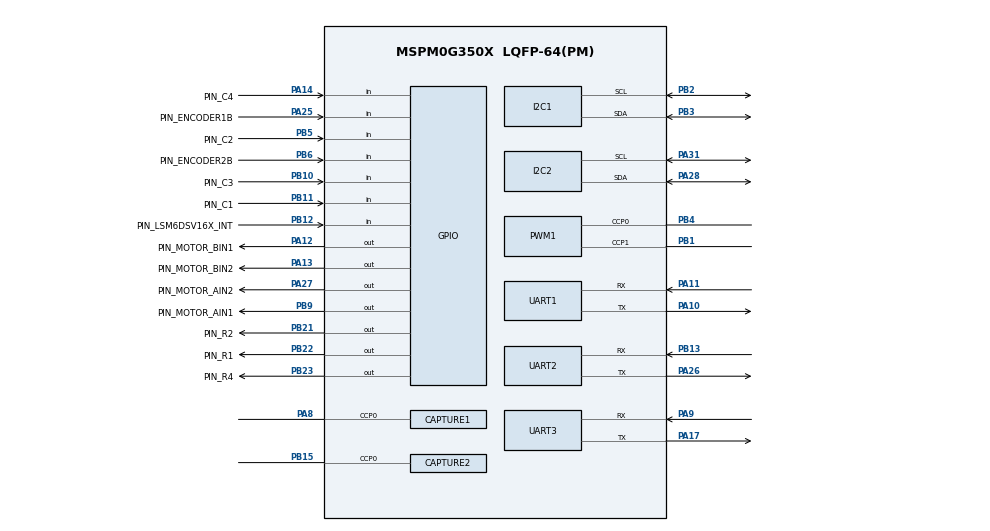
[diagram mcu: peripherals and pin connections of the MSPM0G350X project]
/**
 * @cliArgs --device "MSPM0G350X" --part "Default" --package "LQFP-64(PM)" --product "mspm0_sdk@2.05.00.05"
 * @versions {"tool":"1.24.0+4110"}
 */

/**
 * Import the modules used in this configuration.
 */
const CAPTURE  = scripting.addModule("/ti/driverlib/CAPTURE", {}, false);
const CAPTURE1 = CAPTURE.addInstance();
const CAPTURE2 = CAPTURE.addInstance();
const DMA      = scripting.addModule("/ti/driverlib/DMA");
const GPIO     = scripting.addModule("/ti/driverlib/GPIO", {}, false);
const GPIO1    = GPIO.addInstance();
const GPIO2    = GPIO.addInstance();
const GPIO3    = GPIO.addInstance();
const GPIO4    = GPIO.addInstance();
const I2C      = scripting.addModule("/ti/driverlib/I2C", {}, false);
const I2C1     = I2C.addInstance();
const I2C2     = I2C.addInstance();
const PWM      = scripting.addModule("/ti/driverlib/PWM", {}, false);
const PWM1     = PWM.addInstance();
const SYSCTL   = scripting.addModule("/ti/driverlib/SYSCTL");
const TIMER    = scripting.addModule("/ti/driverlib/TIMER", {}, false);
const TIMER1   = TIMER.addInstance();
const TIMER2   = TIMER.addInstance();
const UART     = scripting.addModule("/ti/driverlib/UART", {}, false);
const UART1    = UART.addInstance();
const UART2    = UART.addInstance();
const UART3    = UART.addInstance();

/**
 * Write custom configuration values to the imported modules.
 */
const divider7       = system.clockTree["PLL_PDIV"];
divider7.divideValue = 2;

const divider9       = system.clockTree["UDIV"];
divider9.divideValue = 2;

const multiplier2         = system.clockTree["PLL_QDIV"];
multiplier2.multiplyValue = 5;

const mux8       = system.clockTree["HSCLKMUX"];
mux8.inputSelect = "HSCLKMUX_SYSPLL2X";

CAPTURE1.$name                              = "ENCODER1A";
CAPTURE1.timerPeriod                        = "1 ms";
CAPTURE1.timerClkPrescale                   = 2;
CAPTURE1.interrupts                         = ["CC0_DN"];
CAPTURE1.timerStartTimer                    = true;
CAPTURE1.peripheral.ccp0Pin.$assign         = "PA8";
CAPTURE1.ccp0PinConfig.hideOutputInversion  = scripting.forceWrite(false);
CAPTURE1.ccp0PinConfig.onlyInternalResistor = scripting.forceWrite(false);
CAPTURE1.ccp0PinConfig.passedPeripheralType = scripting.forceWrite("Digital");
CAPTURE1.ccp0PinConfig.$name                = "ti_driverlib_gpio_GPIOPinGeneric6";

const Board = scripting.addModule("/ti/driverlib/Board", {}, false);

CAPTURE2.$name                              = "ENCODER2A";
CAPTURE2.timerPeriod                        = "1 ms";
CAPTURE2.timerStartTimer                    = true;
CAPTURE2.interrupts                         = ["CC0_DN"];
CAPTURE2.timerClkPrescale                   = 2;
CAPTURE2.peripheral.ccp0Pin.$assign         = "PB15";
CAPTURE2.ccp0PinConfig.hideOutputInversion  = scripting.forceWrite(false);
CAPTURE2.ccp0PinConfig.onlyInternalResistor = scripting.forceWrite(false);
CAPTURE2.ccp0PinConfig.passedPeripheralType = scripting.forceWrite("Digital");
CAPTURE2.ccp0PinConfig.$name                = "ti_driverlib_gpio_GPIOPinGeneric7";

GPIO1.$name                              = "GPIO_KEY";
GPIO1.associatedPins.create(8);
GPIO1.associatedPins[0].$name            = "PIN_C3";
GPIO1.associatedPins[0].direction        = "INPUT";
GPIO1.associatedPins[0].internalResistor = "PULL_UP";
GPIO1.associatedPins[0].assignedPort     = "PORTB";
GPIO1.associatedPins[0].assignedPin      = "10";
GPIO1.associatedPins[0].pin.$assign      = "PB10";
GPIO1.associatedPins[1].$name            = "PIN_C4";
GPIO1.associatedPins[1].direction        = "INPUT";
GPIO1.associatedPins[1].internalResistor = "PULL_UP";
GPIO1.associatedPins[1].assignedPort     = "PORTA";
GPIO1.associatedPins[1].assignedPin      = "14";
GPIO1.associatedPins[1].pin.$assign      = "PA14";
GPIO1.associatedPins[2].$name            = "PIN_R1";
GPIO1.associatedPins[2].initialValue     = "SET";
GPIO1.associatedPins[2].assignedPort     = "PORTB";
GPIO1.associatedPins[2].assignedPin      = "22";
GPIO1.associatedPins[2].pin.$assign      = "PB22";
GPIO1.associatedPins[3].$name            = "PIN_R2";
GPIO1.associatedPins[3].initialValue     = "SET";
GPIO1.associatedPins[3].assignedPort     = "PORTB";
GPIO1.associatedPins[3].assignedPin      = "21";
GPIO1.associatedPins[3].pin.$assign      = "PB21";
GPIO1.associatedPins[4].$name            = "PIN_R3";
GPIO1.associatedPins[4].initialValue     = "SET";
GPIO1.associatedPins[4].assignedPort     = "PORTB";
GPIO1.associatedPins[4].assignedPin      = "26";
GPIO1.associatedPins[5].$name            = "PIN_R4";
GPIO1.associatedPins[5].initialValue     = "SET";
GPIO1.associatedPins[5].assignedPort     = "PORTB";
GPIO1.associatedPins[5].assignedPin      = "23";
GPIO1.associatedPins[5].pin.$assign      = "PB23";
GPIO1.associatedPins[6].$name            = "PIN_C1";
GPIO1.associatedPins[6].direction        = "INPUT";
GPIO1.associatedPins[6].internalResistor = "PULL_UP";
GPIO1.associatedPins[6].assignedPort     = "PORTB";
GPIO1.associatedPins[6].assignedPin      = "11";
GPIO1.associatedPins[6].pin.$assign      = "PB11";
GPIO1.associatedPins[7].$name            = "PIN_C2";
GPIO1.associatedPins[7].direction        = "INPUT";
GPIO1.associatedPins[7].internalResistor = "PULL_UP";
GPIO1.associatedPins[7].assignedPort     = "PORTB";
GPIO1.associatedPins[7].assignedPin      = "5";
GPIO1.associatedPins[7].pin.$assign      = "PB5";

GPIO2.$name                         = "GPIO_MOTOR";
GPIO2.associatedPins.create(4);
GPIO2.associatedPins[0].$name       = "PIN_MOTOR_AIN1";
GPIO2.associatedPins[0].pin.$assign = "PB9";
GPIO2.associatedPins[1].$name       = "PIN_MOTOR_AIN2";
GPIO2.associatedPins[1].pin.$assign = "PA27";
GPIO2.associatedPins[2].$name       = "PIN_MOTOR_BIN1";
GPIO2.associatedPins[2].pin.$assign = "PA12";
GPIO2.associatedPins[3].$name       = "PIN_MOTOR_BIN2";
GPIO2.associatedPins[3].pin.$assign = "PA13";

GPIO3.$name                               = "GPIO_ENCODER";
GPIO3.associatedPins.create(2);
GPIO3.associatedPins[0].$name             = "PIN_ENCODER1B";
GPIO3.associatedPins[0].direction         = "INPUT";
GPIO3.associatedPins[0].pin.$assign       = "PA25";
GPIO3.associatedPins[1].direction         = "INPUT";
GPIO3.associatedPins[1].polarity          = "RISE";
GPIO3.associatedPins[1].interruptPriority = "1";
GPIO3.associatedPins[1].$name             = "PIN_ENCODER2B";
GPIO3.associatedPins[1].pin.$assign       = "PB6";

GPIO4.$name                               = "GPIO_LSM6DSV16X";
GPIO4.associatedPins[0].$name             = "PIN_LSM6DSV16X_INT";
GPIO4.associatedPins[0].direction         = "INPUT";
GPIO4.associatedPins[0].interruptEn       = true;
GPIO4.associatedPins[0].polarity          = "RISE";
GPIO4.associatedPins[0].interruptPriority = "3";
GPIO4.associatedPins[0].pin.$assign       = "PB12";

I2C1.$name                             = "I2C_OLED";
I2C1.basicEnableController             = true;
I2C1.basicControllerStandardBusSpeed   = "Fast";
I2C1.peripheral.sdaPin.$assign         = "PB3";
I2C1.peripheral.sclPin.$assign         = "PB2";
I2C1.sdaPinConfig.hideOutputInversion  = scripting.forceWrite(false);
I2C1.sdaPinConfig.onlyInternalResistor = scripting.forceWrite(false);
I2C1.sdaPinConfig.passedPeripheralType = scripting.forceWrite("Digital");
I2C1.sdaPinConfig.$name                = "ti_driverlib_gpio_GPIOPinGeneric0";
I2C1.sclPinConfig.hideOutputInversion  = scripting.forceWrite(false);
I2C1.sclPinConfig.onlyInternalResistor = scripting.forceWrite(false);
I2C1.sclPinConfig.passedPeripheralType = scripting.forceWrite("Digital");
I2C1.sclPinConfig.$name                = "ti_driverlib_gpio_GPIOPinGeneric1";

I2C2.$name                             = "I2C_LSM6DSV16X";
I2C2.basicEnableController             = true;
I2C2.peripheral.$assign                = "I2C0";
I2C2.peripheral.sdaPin.$assign         = "PA28";
I2C2.peripheral.sclPin.$assign         = "PA31";
I2C2.sdaPinConfig.hideOutputInversion  = scripting.forceWrite(false);
I2C2.sdaPinConfig.onlyInternalResistor = scripting.forceWrite(false);
I2C2.sdaPinConfig.passedPeripheralType = scripting.forceWrite("Digital");
I2C2.sdaPinConfig.$name                = "ti_driverlib_gpio_GPIOPinGeneric8";
I2C2.sclPinConfig.hideOutputInversion  = scripting.forceWrite(false);
I2C2.sclPinConfig.onlyInternalResistor = scripting.forceWrite(false);
I2C2.sclPinConfig.passedPeripheralType = scripting.forceWrite("Digital");
I2C2.sclPinConfig.$name                = "ti_driverlib_gpio_GPIOPinGeneric9";

PWM1.clockDivider                       = 2;
PWM1.timerCount                         = 4000;
PWM1.timerStartTimer                    = true;
PWM1.$name                              = "PWM_MOTOR_1";
PWM1.pwmMode                            = "EDGE_ALIGN_UP";
PWM1.peripheral.ccp0Pin.$assign         = "PB4";
PWM1.peripheral.ccp1Pin.$assign         = "PB1";
PWM1.PWM_CHANNEL_0.$name                = "ti_driverlib_pwm_PWMTimerCC0";
PWM1.PWM_CHANNEL_1.$name                = "ti_driverlib_pwm_PWMTimerCC1";
PWM1.ccp0PinConfig.direction            = scripting.forceWrite("OUTPUT");
PWM1.ccp0PinConfig.hideOutputInversion  = scripting.forceWrite(false);
PWM1.ccp0PinConfig.onlyInternalResistor = scripting.forceWrite(false);
PWM1.ccp0PinConfig.passedPeripheralType = scripting.forceWrite("Digital");
PWM1.ccp0PinConfig.$name                = "ti_driverlib_gpio_GPIOPinGeneric2";
PWM1.ccp1PinConfig.direction            = scripting.forceWrite("OUTPUT");
PWM1.ccp1PinConfig.hideOutputInversion  = scripting.forceWrite(false);
PWM1.ccp1PinConfig.onlyInternalResistor = scripting.forceWrite(false);
PWM1.ccp1PinConfig.passedPeripheralType = scripting.forceWrite("Digital");
PWM1.ccp1PinConfig.$name                = "ti_driverlib_gpio_GPIOPinGeneric5";

SYSCTL.forceDefaultClkConfig = true;
SYSCTL.clockTreeEn           = true;
scripting.suppress("For best practices when the CPUCLK is running at 32MHz and above, clear the flash status bit using DL_FlashCTL_executeClearStatus\\(\\) before executing any flash operation\\. Otherwise there may be false positives\\.", SYSCTL);

TIMER1.$name            = "CLOCK_ZYD";
TIMER1.timerClkDiv      = 4;
TIMER1.timerMode        = "PERIODIC";
TIMER1.interrupts       = ["ZERO"];
TIMER1.timerStartTimer  = true;
TIMER1.timerClkPrescale = 50;
TIMER1.timerPeriod      = "10 ms";

TIMER2.$name            = "CLOCK_PTZ";
TIMER2.timerClkDiv      = 8;
TIMER2.timerMode        = "PERIODIC";
TIMER2.timerClkPrescale = 10;
TIMER2.interrupts       = ["ZERO"];
TIMER2.timerStartTimer  = true;
TIMER2.timerPeriod      = "80 ms";

UART1.targetBaudRate                       = 115200;
UART1.$name                                = "UART_K230";
UART1.enabledDMARXTriggers                 = "DL_UART_DMA_INTERRUPT_RX";
UART1.enabledInterrupts                    = ["RX"];
UART1.txFifoThreshold                      = "DL_UART_TX_FIFO_LEVEL_EMPTY";
UART1.enableFIFO                           = true;
UART1.rxFifoThreshold                      = "DL_UART_RX_FIFO_LEVEL_FULL";
UART1.peripheral.$assign                   = "UART0";
UART1.peripheral.rxPin.$assign             = "PA11";
UART1.peripheral.txPin.$assign             = "PA10";
UART1.txPinConfig.direction                = scripting.forceWrite("OUTPUT");
UART1.txPinConfig.hideOutputInversion      = scripting.forceWrite(false);
UART1.txPinConfig.onlyInternalResistor     = scripting.forceWrite(false);
UART1.txPinConfig.passedPeripheralType     = scripting.forceWrite("Digital");
UART1.txPinConfig.$name                    = "ti_driverlib_gpio_GPIOPinGeneric3";
UART1.rxPinConfig.hideOutputInversion      = scripting.forceWrite(false);
UART1.rxPinConfig.onlyInternalResistor     = scripting.forceWrite(false);
UART1.rxPinConfig.passedPeripheralType     = scripting.forceWrite("Digital");
UART1.rxPinConfig.$name                    = "ti_driverlib_gpio_GPIOPinGeneric4";
UART1.DMA_CHANNEL_RX.$name                 = "DMA_CH0";
UART1.DMA_CHANNEL_RX.addressMode           = "f2b";
UART1.DMA_CHANNEL_RX.srcLength             = "BYTE";
UART1.DMA_CHANNEL_RX.dstLength             = "BYTE";
UART1.DMA_CHANNEL_RX.configureTransferSize = true;
UART1.DMA_CHANNEL_RX.enableInterrupt       = true;
UART1.DMA_CHANNEL_RX.transferSize          = 7;
UART1.DMA_CHANNEL_RX.peripheral.$assign    = "DMA_CH0";

UART2.$name                                = "UART_FORWORD";
UART2.targetBaudRate                       = 115200;
UART2.enabledDMARXTriggers                 = "DL_UART_DMA_INTERRUPT_RX";
UART2.enabledDMATXTriggers                 = "DL_UART_DMA_INTERRUPT_TX";
UART2.enabledInterrupts                    = ["DMA_DONE_RX","EOT_DONE"];
UART2.txFifoThreshold                      = "DL_UART_TX_FIFO_LEVEL_EMPTY";
UART2.rxFifoThreshold                      = "DL_UART_RX_FIFO_LEVEL_ONE_ENTRY";
UART2.peripheral.rxPin.$assign             = "PB13";
UART2.peripheral.txPin.$assign             = "PA26";
UART2.txPinConfig.$name                    = "ti_driverlib_gpio_GPIOPinGeneric10";
UART2.txPinConfig.direction                = scripting.forceWrite("OUTPUT");
UART2.txPinConfig.hideOutputInversion      = scripting.forceWrite(false);
UART2.txPinConfig.onlyInternalResistor     = scripting.forceWrite(false);
UART2.txPinConfig.passedPeripheralType     = scripting.forceWrite("Digital");
UART2.rxPinConfig.$name                    = "ti_driverlib_gpio_GPIOPinGeneric11";
UART2.rxPinConfig.hideOutputInversion      = scripting.forceWrite(false);
UART2.rxPinConfig.onlyInternalResistor     = scripting.forceWrite(false);
UART2.rxPinConfig.passedPeripheralType     = scripting.forceWrite("Digital");
UART2.DMA_CHANNEL_RX.$name                 = "DMA_CH1";
UART2.DMA_CHANNEL_RX.addressMode           = "f2b";
UART2.DMA_CHANNEL_RX.srcLength             = "BYTE";
UART2.DMA_CHANNEL_RX.dstLength             = "BYTE";
UART2.DMA_CHANNEL_RX.enableInterrupt       = true;
UART2.DMA_CHANNEL_RX.configureTransferSize = true;
UART2.DMA_CHANNEL_RX.transferSize          = 30;
UART2.DMA_CHANNEL_RX.transferMode          = "FULL_CH_REPEAT_SINGLE";
UART2.DMA_CHANNEL_RX.peripheral.$assign    = "DMA_CH1";
UART2.DMA_CHANNEL_TX.$name                 = "DMA_CH2";
UART2.DMA_CHANNEL_TX.addressMode           = "b2f";
UART2.DMA_CHANNEL_TX.srcLength             = "BYTE";
UART2.DMA_CHANNEL_TX.dstLength             = "BYTE";
UART2.DMA_CHANNEL_TX.configureTransferSize = true;
UART2.DMA_CHANNEL_TX.transferSize          = 29;
UART2.DMA_CHANNEL_TX.enableInterrupt       = true;
UART2.DMA_CHANNEL_TX.peripheral.$assign    = "DMA_CH2";

UART3.$name                                = "UART_BACKWARD";
UART3.targetBaudRate                       = 115200;
UART3.enabledDMATXTriggers                 = "DL_UART_DMA_INTERRUPT_TX";
UART3.enabledInterrupts                    = ["DMA_DONE_TX","EOT_DONE"];
UART3.peripheral.rxPin.$assign             = "PA9";
UART3.peripheral.txPin.$assign             = "PA17";
UART3.txPinConfig.$name                    = "ti_driverlib_gpio_GPIOPinGeneric12";
UART3.txPinConfig.direction                = scripting.forceWrite("OUTPUT");
UART3.txPinConfig.hideOutputInversion      = scripting.forceWrite(false);
UART3.txPinConfig.onlyInternalResistor     = scripting.forceWrite(false);
UART3.txPinConfig.passedPeripheralType     = scripting.forceWrite("Digital");
UART3.rxPinConfig.$name                    = "ti_driverlib_gpio_GPIOPinGeneric13";
UART3.rxPinConfig.hideOutputInversion      = scripting.forceWrite(false);
UART3.rxPinConfig.onlyInternalResistor     = scripting.forceWrite(false);
UART3.rxPinConfig.passedPeripheralType     = scripting.forceWrite("Digital");
UART3.DMA_CHANNEL_TX.$name                 = "DMA_CH3";
UART3.DMA_CHANNEL_TX.srcLength             = "BYTE";
UART3.DMA_CHANNEL_TX.dstLength             = "BYTE";
UART3.DMA_CHANNEL_TX.addressMode           = "b2f";
UART3.DMA_CHANNEL_TX.configureTransferSize = true;
UART3.DMA_CHANNEL_TX.enableInterrupt       = true;
UART3.DMA_CHANNEL_TX.transferSize          = 16;

/**
 * Pinmux solution for unlocked pins/peripherals. This ensures that minor changes to the automatic solver in a future
 * version of the tool will not impact the pinmux you originally saw.  These lines can be completely deleted in order to
 * re-solve from scratch.
 */
CAPTURE1.peripheral.$suggestSolution             = "TIMA0";
Board.peripheral.$suggestSolution                = "DEBUGSS";
Board.peripheral.swclkPin.$suggestSolution       = "PA20";
Board.peripheral.swdioPin.$suggestSolution       = "PA19";
CAPTURE2.peripheral.$suggestSolution             = "TIMG7";
GPIO1.associatedPins[4].pin.$suggestSolution     = "PB26";
I2C1.peripheral.$suggestSolution                 = "I2C1";
PWM1.peripheral.$suggestSolution                 = "TIMA1";
TIMER1.peripheral.$suggestSolution               = "TIMG6";
TIMER2.peripheral.$suggestSolution               = "TIMG0";
UART2.peripheral.$suggestSolution                = "UART3";
UART3.peripheral.$suggestSolution                = "UART1";
UART3.DMA_CHANNEL_TX.peripheral.$suggestSolution = "DMA_CH3";
